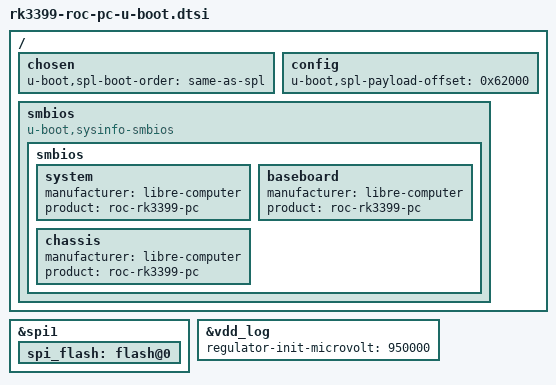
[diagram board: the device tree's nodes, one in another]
// SPDX-License-Identifier: GPL-2.0+
/*
 * Copyright (C) 2019 Levin Du <djw@t-chip.com.cn>
 */

#include "rk3399-u-boot.dtsi"
#include "rk3399-sdram-lpddr4-800-1866-100.dtsi"

/ {
	chosen {
		u-boot,spl-boot-order = "same-as-spl", &dmc, &spi_flash, &sdhci, &sdmmc;
	};

	config {
		u-boot,spl-payload-offset = <0x62000>; /* @ 384KB */
	};

	smbios {
		compatible = "u-boot,sysinfo-smbios";

		smbios {
			system {
				manufacturer = "libre-computer";
				product = "roc-rk3399-pc";
			};

			baseboard {
				manufacturer = "libre-computer";
				product = "roc-rk3399-pc";
			};

			chassis {
				manufacturer = "libre-computer";
				product = "roc-rk3399-pc";
			};
		};
	};

};

&spi1 {
	spi_flash: flash@0 {
		bootph-all;
	};
};

&vdd_log {
	regulator-init-microvolt = <950000>;
};
